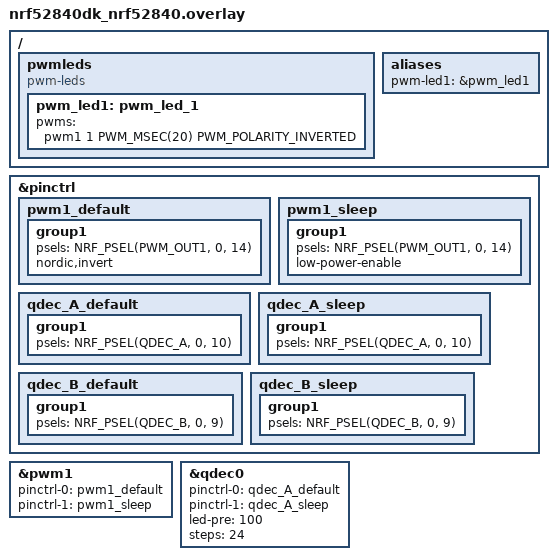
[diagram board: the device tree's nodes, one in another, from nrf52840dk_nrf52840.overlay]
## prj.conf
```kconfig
CONFIG_STDOUT_CONSOLE=y
CONFIG_PRINTK=y
CONFIG_PWM=y
CONFIG_LOG=y
CONFIG_LOG_PRINTK=y
CONFIG_LOG_MODE_IMMEDIATE=y
CONFIG_PWM_LOG_LEVEL_DBG=y
CONFIG_NEWLIB_LIBC_FLOAT_PRINTF=y
CONFIG_NEWLIB_LIBC=y

CONFIG_SENSOR=y
CONFIG_QDEC_NRFX=y
```

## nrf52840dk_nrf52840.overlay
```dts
// To get started, press Ctrl+Space to bring up the completion menu and view the available nodes.
// For more help, browse the DeviceTree documentation at https://docs.zephyrproject.org/latest/guides/dts/index.html
/{    
    pwmleds {
		compatible = "pwm-leds";		
		pwm_led1: pwm_led_1 {
			pwms = <&pwm1 1 PWM_MSEC(20) PWM_POLARITY_INVERTED>;
		};
	};

    /* These aliases are provided for compatibility with samples */
	aliases {
		pwm-led1 = &pwm_led1;
	};
};


&pinctrl {

    pwm1_default: pwm1_default {
		group1 {
			psels = <NRF_PSEL(PWM_OUT1, 0, 14)>;
			nordic,invert;
		};
	};

	pwm1_sleep: pwm1_sleep {
		group1 {
			psels = <NRF_PSEL(PWM_OUT1, 0, 14)>;
			low-power-enable;
		};
	};

};

&pwm1 {
	status = "okay";
	pinctrl-0 = <&pwm1_default>;
	pinctrl-1 = <&pwm1_sleep>;
	pinctrl-names = "default", "sleep";
};

&pinctrl {

    qdec_A_default: qdec_A_default {
		group1 {
			psels = <NRF_PSEL(QDEC_A, 0, 10)>;
		};
	};

	qdec_A_sleep: qdec_A_sleep {
		group1 {
			psels = <NRF_PSEL(QDEC_A, 0, 10)>;
		};
	};

	qdec_B_default: qdec_B_default {
		group1 {
			psels = <NRF_PSEL(QDEC_B, 0, 9)>;
		};
	};

	qdec_B_sleep: qdec_B_sleep {
		group1 {
			psels = <NRF_PSEL(QDEC_B, 0, 9)>;
		};
	};

};

&qdec0 {
	status = "okay";
	// enable-pin = <8>;
	// a-pin = <10>;
	// b-pin = <9>;
	pinctrl-0 = <&qdec_A_default>;
	pinctrl-1 = <&qdec_A_sleep>;
	// pinctrl-2 = <&qdec_B_default>;
	// pinctrl-3 = <&qdec_B_sleep>;
	pinctrl-names = "default", "sleep";
	// led-pin = <15>;
	led-pre = <100>;
	steps = <24>;
};
```

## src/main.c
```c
/*
 * Copyright (c) 2016 Intel Corporation
 * Copyright (c) 2020 Nordic Semiconductor ASA
 *
 * SPDX-License-Identifier: Apache-2.0
 */

/**
 * @file Sample app to demonstrate PWM.
 */
#include <stdio.h>
#include <zephyr.h>
#include <sys/printk.h>
#include <device.h>
#include <drivers/pwm.h>
#include <drivers/gpio.h>
#include <drivers/sensor.h>

static const struct pwm_dt_spec pwm_led0 = PWM_DT_SPEC_GET(DT_ALIAS(pwm_led0));
static const struct pwm_dt_spec pwm_led1 = PWM_DT_SPEC_GET(DT_ALIAS(pwm_led1));


#define MIN_PERIOD PWM_SEC(1U) / 512U
#define MAX_PERIOD PWM_SEC(1U)

void main(void)
{
	const struct device *dev;
	const struct device *qdec;
	
	uint32_t max_period;
	uint32_t period;
	uint8_t dir = 0U;
	int ret;
	float factor=0;
	
	

	dev = device_get_binding("GPIO_0");
	if (dev == NULL) {
		return;
	}

	qdec = device_get_binding("QDEC");
	if (qdec == NULL) {
		printf("error: no QDEC device\n");
		return;
	}

	ret = gpio_pin_configure(dev, 26, GPIO_OUTPUT_ACTIVE | GPIO_ACTIVE_LOW);
	if (ret < 0) {
		return;
	}

	ret = gpio_pin_configure(dev, 27, GPIO_OUTPUT_ACTIVE | GPIO_ACTIVE_LOW);
	if (ret < 0) {
		return;
	}

	gpio_pin_set(dev,26,0);
	gpio_pin_set(dev,27,1);

	printk("PWM-based blinky\n");

	if (!device_is_ready(pwm_led0.dev)) {
		printk("Error: PWM device %s is not ready\n",
		       pwm_led0.dev->name);
		return;
	}

	if (!device_is_ready(pwm_led1.dev)) {
		printk("Error: PWM device %s is not ready\n",
		       pwm_led1.dev->name);
		return;
	}

	/*
	 * In case the default MAX_PERIOD value cannot be set for
	 * some PWM hardware, decrease its value until it can.
	 *
	 * Keep its value at least MIN_PERIOD * 4 to make sure
	 * the sample changes frequency at least once.
	 */
	printk("Calibrating for channel %d...\n", pwm_led0.channel);
	max_period = MAX_PERIOD;
	while (pwm_set_dt(&pwm_led0, max_period, max_period / 2U)) {
		max_period /= 2U;
		if (max_period < (4U * MIN_PERIOD)) {
			printk("Error: PWM device "
			       "does not support a period at least %lu\n",
			       4U * MIN_PERIOD);
			return;
		}
	}

	printk("Calibrating for channel %d...\n", pwm_led1.channel);
	max_period = MAX_PERIOD;
	while (pwm_set_dt(&pwm_led1, max_period, max_period / 2U)) {
		max_period /= 2U;
		if (max_period < (4U * MIN_PERIOD)) {
			printk("Error: PWM device "
			       "does not support a period at least %lu\n",
			       4U * MIN_PERIOD);
			return;
		}
	}

	printk("Done calibrating; maximum/minimum periods %u/%lu usec\n",
	       max_period, MIN_PERIOD);

	period = MIN_PERIOD;
	
	while (factor <= 10) {
		
		
		printf("factor %.2f\r\n", (float)(factor / 10));
		
		ret = pwm_set_dt(&pwm_led0, period, period * (factor / 10));
		if (ret) {
			printk("Error %d: failed to set pulse width\n", ret);
			return;
		}
		ret = pwm_set_dt(&pwm_led1, period, period * (factor / 10));
		if (ret) {
			printk("Error %d: failed to set pulse width\n", ret);
			return;
		}

		if(factor == 10) 
		{			
			dir = 1;
			gpio_pin_set(dev,26,1);
			gpio_pin_set(dev,27,0);
		} else if (factor == 0)
		{
			dir = 0;
			gpio_pin_set(dev,26,0);
			gpio_pin_set(dev,27,1);
		}
		if (dir == 0) {
			factor = factor + 1;
		}
		else {
			factor = factor - 1;
		}

		struct sensor_value value;

		ret = sensor_sample_fetch(qdec);
		if (ret) {
			printf("sensor_sample_fetch failed returns: %d\n", ret);
			break;
		}

		ret = sensor_channel_get(qdec, SENSOR_CHAN_ROTATION, &value);
		if (ret) {
			printf("sensor_channel_get failed returns: %d\n", ret);
			break;
		}

		printf("Position is %d\n", value.val1);
		
		k_sleep(K_SECONDS(2U));
	}
}
```
